# CY8C5888LTI_LP097 register map
File version: 0.1
Registers are 8-bit, read-write, no defined reset value unless marked. A register's access mark holds for its fields unless they carry their own. Offsets are from the block's base; [hi:lo] are bit positions; 'fields as' and 'values as' point back to an identical list.

## I2C_Master
Base 0x00000000
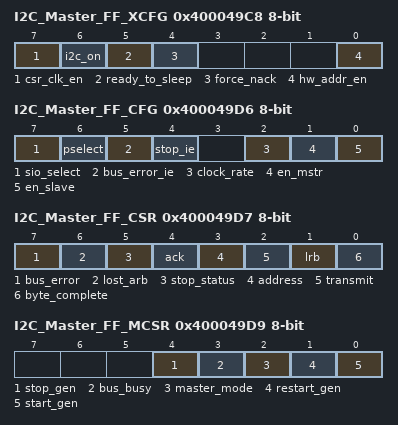
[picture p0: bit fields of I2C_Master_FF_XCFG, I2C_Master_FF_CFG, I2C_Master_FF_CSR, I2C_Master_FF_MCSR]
0x400049C8 I2C_Master_FF_XCFG — I2C Extended Configuration Register
  [7] csr_clk_en — This bit is used for gating system clock for the blocks core logic that is not associated with AHB interface. Clock is made available to the core logic only when this bit is set to 1 and the input pin ext_clk_en is also active. If either of them is not active, the blocks core logic does not receive the system clock.
  [6] i2c_on — This bit should be set by the user during initial block configuration if the user wants to use the I2C block as wake-up source. Only when this bit set along with other bits mentioned in the sleep mode section, the I2C wakes up system from sleep on address match.
  [5] ready_to_sleep ro — Once the user sets the force_nack bit, the I2C block sets this bit if I2C is not busy or it waits for ongoing transaction to be completed and then sets this bit. As long as this bit is set, the I2C block is going to nack all the transactions.Clearing force_nack bit automatically clears this bit. HW clears this bit automatically on assertion of PD (Power Down)
  [4] force_nack — This bit must be set by the user before putting the device to sleep and wait for ready_to_sleep status bit to be set. This can be cleared by user by writing '0' and the HW clears it automatically on assertion of PD(Power Down)
  [0] hw_addr_en — When this bit is set to a '1', hardware address compare is enabled. On an address match, an interrupt is generated, CSR register bit 3 is set, and the clock is stalled until the CPU writes a 0 into the CSR register bit 3. The address is automatically ACKed on a match. On an address mismatch,no interrupt is generated, clock is not stalled, and bit 3 in the CSR register is set. The CPU must write a 0 into the CSR register bit 3 to clear it. The address is automatically NACKed on a mismatch. You must configure the compare address in the ADR register. When this bit is set to a '0', software address compare is enabled. An interrupt is generated, the clock is stalled, and CSR register bit 3 is set when the received address byte is available in the Data register; to enable the CPU to do a firmware address compare. The clock is stalled until the CPU writes a 0 into the CSR register bit 3. The functionality of this bit is independent of the data buffering mode.
0x400049CA I2C_Master_FF_ADDR — I2C Slave Adddress Register
  [6:0] slave_address — These seven bits hold the slave's own device address. These bits are held zero if I2C_CFG.en_mstr and I2C_CFG.en_slave are both zero.
0x400049D6 I2C_Master_FF_CFG — I2C Configuration Register
  [7] sio_select — I2C Pin Select for SCL/SDA lines from SIO1/SIO2, 0 = SCL and SDA lines get their inputs from SIO1 module.sclk_str1 and sda_ack1 are driven to SIO1 module and they get asserted once device wakes up from sleep. 1 = SCL and SDA lines get their inputs from SIO2 module. sclk_str2 and sda_ack2 are driven to SIO2 module and they get asserted once device wakes up from sleep. This bit is valid only when I2C.CFG[6] is asserted.
  [6] pselect — I2C Pin Select for SCL/SDA lines from GPIO/SIO, 0 = SCL and SDA lines get their inputs from GPIO module.sclk_str0 and sda_ack0 are driven to GPIO module and they get asserted once device wakes up from sleep. 1 = SCL and SDA lines get their inputs from one of the SIO Blocks that is chosen based on the configuration of bit I2C.CFG[7]
  [5] bus_error_ie — Bus Error Interrupt Enable 0 disabled 1 enabled. An interrupt is generated on the detection of a Bus error condition.
  [4] stop_ie — Stop Interrupt Enable 0 disabled 1 enabled. An interrupt is generated on the detection of a Stop condition.
  [2] clock_rate — 0 Samples/bit is 16, 1 Samples/bit is 32
  [1] en_mstr — Enables master mode for the device
  [0] en_slave — Enables Slave mode for the device
0x400049D7 I2C_Master_FF_CSR — I2C Control and Status Register
  [7] bus_error — It must be cleared by firmware by writing a '0' to the bit position. It is never cleared by the hardware. 1 a misplaced Start or Stop condition was detected. This bit is held zero if I2C_CFG.en_mstr and I2C_CFG.en_slave are both zero.
  [6] lost_arb — This bit is set immediately on lost arbitration; however, it does not cause an interrupt. This status may be checked after the following Byte Complete interrupt. Any Start detect or a write to the Start or Restart generate bits (MCSR register), when operating in Master mode, will also clear the bit. 1 lost Arbitration. This bit is held zero if I2C_CFG.en_mstr is zero.
  [5] stop_status — It must be cleared by firmware with write of '0' to the bit position. It is never cleared by the hardware. 1 a Stop condition was detected. This bit is held zero if I2C_CFG.en_mstr and I2C_CFG.en_slave are both zero.
  [4] ack — Acknowledge Out. Bit is automatically cleared by hardware on a Byte Complete event. 0 nack the last received byte. 1 ack the last received byte
  [3] address — It must be cleared by firmware with write of '0' to the bit position. 1 the received byte is a slave address. This bit is held zero if I2C_CFG.en_mstr and I2C_CFG.en_slave are both zero
  [2] transmit — Bit is set by firmware to define the direction of the byte transfer. Any Start detect will clear the bit. 0 receive mode 1 transmit mode. This bit is held zero if I2C_CFG.en_mstr and I2C_CFG.en_slave are both zero.
  [1] lrb — Last Received Bit. The value of the 9th bit in a Transmit sequence, which is the acknowledge bit from the receiver. Any Start detect or a write to the Start or Restart generate bits, when operating in Master mode, will also clear the bit. 0 last transmitted byte was ACK'ed by the receiver. 1 last transmitted byte was NACK'ed by the receiver. This bit is held zero if I2C_CFG.en_mstr and I2C_CFG.en_slave are both zero.
  [0] byte_complete — Transmit/Receive Mode: 0 no completed transmit/receive since last cleared by firmware. Any Start detect or a write to the start or Restart generate bits, when operating in Master mode, will also clear the bit. Transmit mode: 1 eight bits of data have been transmitted and an ACK or NACK has been received. Receive mode: 1 eight bits of data have been received. This bit is held zero if I2C_CFG.en_mstr and I2C_CFG.en_slave are both zero.
0x400049D8 I2C_Master_FF_DATA — I2C Data Register
  [7:0] data — Read received data or write data to transmit. These bits are held zero if I2C_CFG.en_mstr and I2C_CFG.en_slave are both zero.
0x400049D9 I2C_Master_FF_MCSR — Master Control and Status Register: I2C_MCSR
  [4] stop_gen — This bit is set only for master transmitter and used at the end of byte transfer. After byte complete status is set, if this bit is set followed by the Transmit bit in I2C.CSR register, Stop condition is generated after byte complete. This bit is automatically reset to 0 after the Stop, start or Restart has been generated. During data phase, if Stop Gen bit is set to 0, clearing the Transmit bit in I2C.CSR register will also generate a Stop condition. This bit is held zero if I2C_CFG.en_mstr and I2C_CFG.en_slave are both zero.
  [3] bus_busy ro — This bit is set to the following. 0 when a Stop condition is detected (from any bus master). 1 when a Start condition is detected (from any bus master). This bit is held zero if I2C_CFG.en_mstr and I2C_CFG.en_slave are both zero.
  [2] master_mode ro — This bit is set/cleared by hardware when the device is operating as a master. 0 stop condition detected, generated by this device. 1 start condition detected, generated by this device. This bit is held zero if I2C_CFG.en_mstr and I2C_CFG.en_slave are both zero.
  [1] restart_gen — This bit is cleared by hardware when the Restart generation is complete. 0 restart generation complete. 1 generate a Restart condition. This bit is held zero if I2C_CFG.en_mstr and I2C_CFG.en_slave are both zero.
  [0] start_gen — This bit is cleared by hardware when the Start generation is complete. 0 start generation complete. 1 generate a Start condition and send a byte (address) to the I2C bus, if bus is not busy. This bit is held zero if I2C_CFG.en_mstr and I2C_CFG.en_slave are both zero.
0x400049DB I2C_Master_FF_CLK_DIV1 — I2C Clock Divide Factor Register-1
  [7:0] Div — The configuration of this register along with that in register CLK_DIV2 defines the factor by which the SYSCLK will be divided in the I2C block. These bits are held zero if I2C_CFG.en_mstr and I2C_CFG.en_slave are both zero.
0x400049DC I2C_Master_FF_CLK_DIV2 — I2C Clock Divide Factor Register-2
  [1:0] Div — The configuration of this register along with that in register CLK_DIV1 defines the factor by whichthe SYSCLK will be divided in the I2C block. These bits are held zero if I2C_CFG.en_mstr and I2C_CFG.en_slave are both zero.
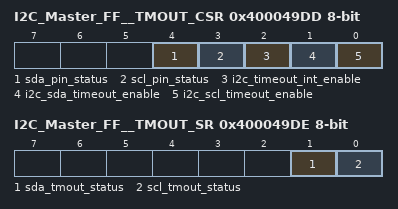
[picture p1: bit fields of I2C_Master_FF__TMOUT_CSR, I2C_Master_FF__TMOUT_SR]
0x400049DD I2C_Master_FF__TMOUT_CSR — I2C Timerout Control and Status Register
  [4] sda_pin_status — SDA Line status.
  [3] scl_pin_status — SCL Line status.
  [2] i2c_timeout_int_enable ro — I2C Timeout interrupt enable.
  [1] i2c_sda_timeout_enable
  [0] i2c_scl_timeout_enable
0x400049DE I2C_Master_FF__TMOUT_SR — I2C Timerout Status Register
  [1] sda_tmout_status — SDA Timeout status.
  [0] scl_tmout_status — SCL Timeout status.
0x400049DF I2C_Master_FF__TMOUT_CFG0 — I2C Timerout Period Configuration Register-0
  [7:0] timeout_period_lowbyte — The configuration of this register along with that in register TMOUT_CFG1 to define the number units before SCL or SDA stuck low timeout triggers the I2C interrupt. The one unit is equal to SYSCLK/1024. The TMOUT_CFG0 defines lower byte of the period.
0x400049E0 I2C_Master_FF__TMOUT_CFG1 — Extended Configuration Register: TMOUT_CFG1
  [3:0] timeout_period_highnibble — The configuration of this register along with that in register TMOUT_CFG1 to define the number units before SCL or SDA stuck low timeout triggers the I2C interrupt. The one unit is equal to SYSCLK/1024. The TMOUT_CFG1 defines higher octet of the period.

## PWM_RG
Base 0x00000000
0x40006425 PWM_RG__COMPARE1 — UDB.D0 - Assigned Compare1 Value
0x40006435 PWM_RG__COMPARE2 — UDB.D1 - Assigned Compare2 Value
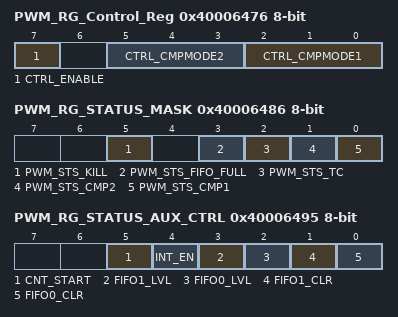
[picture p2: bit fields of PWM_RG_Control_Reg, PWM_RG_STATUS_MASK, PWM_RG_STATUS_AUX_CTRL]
0x40006476 PWM_RG_Control_Reg — UDB Control Register - Assigned Control Register Value
  [7] CTRL_ENABLE — Enable the PWM
  [5:3] CTRL_CMPMODE2 — Compare mode 2
  [2:0] CTRL_CMPMODE1 — Compare mode 1
0x40006486 PWM_RG_STATUS_MASK — UDB Status bits Interrupt Mask Enable Register
  [5] PWM_STS_KILL ro — Enables the Interrupt on Kill
  [3] PWM_STS_FIFO_FULL ro — FIFO Full Status Mask
  [2] PWM_STS_TC ro — Enables the Interrupt on Terminal Count
  [1] PWM_STS_CMP2 ro — Enables the Interrupt on Compare 2
  [0] PWM_STS_CMP1 ro — Enables the Interrupt on Compare 1
0x40006495 PWM_RG_STATUS_AUX_CTRL — UDB Auxilliary Control Register
  [5] CNT_START — FIFO0 clear
    0=E_CNT_START0 (Disable counter); 1=E_CNT_START1 (Enable counter)
  [4] INT_EN
    0=E_INT_EN0 (Interrupt disabled); 1=E_INT_EN1 (Interrupt enabled)
  [3] FIFO1_LVL — FIFO level
    0=E_FIFO_LVL_0 (FIFO LVL: input mode: FIFO not full; output mode: FIFO not empty); 1=E_FIFO_LVL_1 (FIFO LVL: input mode: FIFO at least 1/2 empty; output mode: FIFO at least 1/2 full)
  [2] FIFO0_LVL — FIFO level
    values as FIFO1_LVL
  [1] FIFO1_CLR — FIFO1 clear
    0=E_FIFO_CLR_0 (Normal FIFO operation); 1=E_FIFO_CLR_1 (Clear FIFO state)
  [0] FIFO0_CLR — FIFO0 clear
    values as FIFO1_CLR

## PWM_B
Base 0x00000000
0x40006426 PWM_B_COMPARE_Reg_ — UDB.D0 - Assigned Compare Value
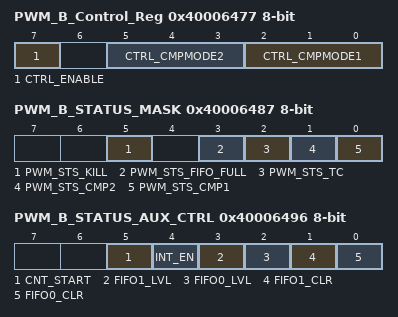
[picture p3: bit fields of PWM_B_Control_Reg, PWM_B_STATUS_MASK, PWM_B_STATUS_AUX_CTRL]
0x40006477 PWM_B_Control_Reg — UDB Control Register - Assigned Control Register Value
  [7] CTRL_ENABLE — Enable the PWM
  [5:3] CTRL_CMPMODE2 — Compare mode 2
  [2:0] CTRL_CMPMODE1 — Compare mode 1
0x40006487 PWM_B_STATUS_MASK — UDB Status bits Interrupt Mask Enable Register
  [5] PWM_STS_KILL ro — Enables the Interrupt on Kill
  [3] PWM_STS_FIFO_FULL ro — FIFO Full Status Mask
  [2] PWM_STS_TC ro — Enables the Interrupt on Terminal Count
  [1] PWM_STS_CMP2 ro — Enables the Interrupt on Compare 2
  [0] PWM_STS_CMP1 ro — Enables the Interrupt on Compare 1
0x40006496 PWM_B_STATUS_AUX_CTRL — UDB Auxilliary Control Register
  [5] CNT_START — FIFO0 clear
    0=E_CNT_START0 (Disable counter); 1=E_CNT_START1 (Enable counter)
  [4] INT_EN
    0=E_INT_EN0 (Interrupt disabled); 1=E_INT_EN1 (Interrupt enabled)
  [3] FIFO1_LVL — FIFO level
    0=E_FIFO_LVL_0 (FIFO LVL: input mode: FIFO not full; output mode: FIFO not empty); 1=E_FIFO_LVL_1 (FIFO LVL: input mode: FIFO at least 1/2 empty; output mode: FIFO at least 1/2 full)
  [2] FIFO0_LVL — FIFO level
    values as FIFO1_LVL
  [1] FIFO1_CLR — FIFO1 clear
    0=E_FIFO_CLR_0 (Normal FIFO operation); 1=E_FIFO_CLR_1 (Clear FIFO state)
  [0] FIFO0_CLR — FIFO0 clear
    values as FIFO1_CLR

## UART
Base 0x00000000
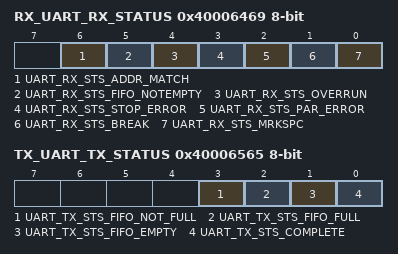
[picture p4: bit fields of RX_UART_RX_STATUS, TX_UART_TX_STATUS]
0x40006469 RX_UART_RX_STATUS — RX status register
  [6] UART_RX_STS_ADDR_MATCH ro, [5] UART_RX_STS_FIFO_NOTEMPTY ro, [4] UART_RX_STS_OVERRUN ro, [3] UART_RX_STS_STOP_ERROR ro, [2] UART_RX_STS_PAR_ERROR ro, [1] UART_RX_STS_BREAK ro, [0] UART_RX_STS_MRKSPC ro
0x40006524 RX_UART_RX_ADDRESS1 — RX Address1 Register
0x40006534 RX_UART_RX_ADDRESS2 — RX Address2 Register
0x40006544 RX_UART_RX_DATA — RX Data Register
0x40006547 TX_UART_TX_DATA — TX Data Register
0x40006565 TX_UART_TX_STATUS — TX status register
  [3] UART_TX_STS_FIFO_NOT_FULL ro, [2] UART_TX_STS_FIFO_FULL ro, [1] UART_TX_STS_FIFO_EMPTY ro, [0] UART_TX_STS_COMPLETE ro
